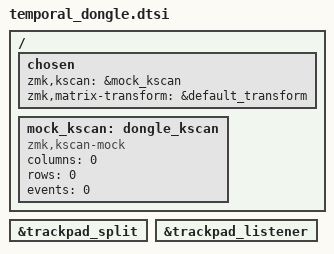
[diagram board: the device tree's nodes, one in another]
/*
 * Copyright (c) 2026 Victor Nguyen
 *
 * SPDX-License-Identifier: MIT
 */

#include "temporal.dtsi"

/ {
    chosen {
        zmk,kscan = &mock_kscan;
        zmk,matrix-transform = &default_transform;
    };

    mock_kscan: dongle_kscan {
        compatible = "zmk,kscan-mock";
        columns = <0>;
        rows = <0>;
        events = <0>;
    };

    // delete this because the dongle does
    // not need matrix gpio pins defined
    // in addition the dongle uses a seeed xiao
    /delete-node/ nice_nano_v2_kscan;
};

&trackpad_split {
    status = "okay";
};

&trackpad_listener {
    status = "okay";
};
